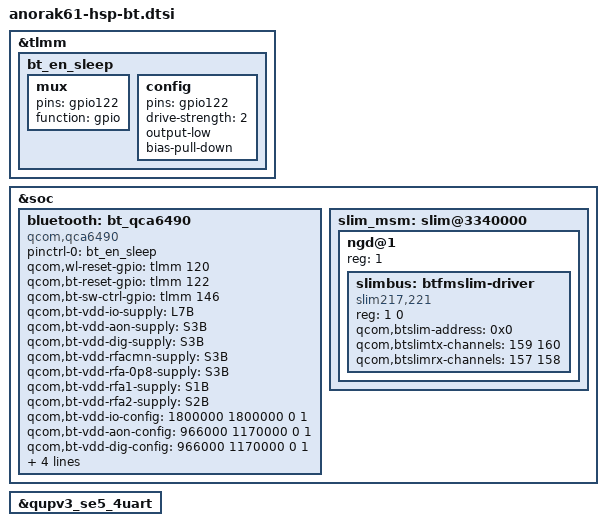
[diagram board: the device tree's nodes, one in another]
#include <dt-bindings/interconnect/qcom,pineapple.h>

&tlmm {
        bt_en_sleep: bt_en_sleep {
                mux {
                        pins = "gpio122";
                        function = "gpio";
                };

                config {
                        pins = "gpio122";
                        drive-strength = <2>;
                        output-low;
                        bias-pull-down;
                };
        };
};


&soc {
	bluetooth: bt_qca6490 {
		compatible = "qcom,qca6490";
		pinctrl-names = "default";
		pinctrl-0 = <&bt_en_sleep>;
		qcom,wl-reset-gpio = <&tlmm 120 0>; /* WL_CTRL */
		qcom,bt-reset-gpio = <&tlmm 122 0>; /* BT_EN */
		qcom,bt-sw-ctrl-gpio = <&tlmm 146 0>; /* SW_CTRL */
		qcom,bt-vdd-io-supply = <&L7B>;  /* IO */
		qcom,bt-vdd-aon-supply = <&S3B>;
		qcom,bt-vdd-dig-supply = <&S3B>; /* BT_CX_MX */
		qcom,bt-vdd-rfacmn-supply = <&S3B>;
		qcom,bt-vdd-rfa-0p8-supply = <&S3B>;
		qcom,bt-vdd-rfa1-supply = <&S1B>; /* RFA 1p7 */
		qcom,bt-vdd-rfa2-supply = <&S2B>; /* RFA 1p2 */
		/* Max Voltages are derived from the buck Max Voltage */
		qcom,bt-vdd-io-config = <1800000 1800000 0 1>;
		qcom,bt-vdd-aon-config = <966000 1170000 0 1>;
		qcom,bt-vdd-dig-config = <966000 1170000 0 1>;
		qcom,bt-vdd-rfacmn-config  = <966000 1170000 0 1>;
		qcom,bt-vdd-rfa-0p8-config  = <966000 1170000 0 1>;
		qcom,bt-vdd-rfa1-config = <1900000 2040000 0 1>;
		qcom,bt-vdd-rfa2-config = <1350000 2024000 0 1>;
	};

	slim_msm: slim@3340000 {
		status =  "ok";
		ngd@1 {
			reg = <1>;
			#address-cells = <1>;
			#size-cells = <1>;
			//slimbus child nodes
			slimbus: btfmslim-driver {
				compatible = "slim217,221";
				reg = <1 0>;
				qcom,btslim-address  = <0x0>; /* BT SLIM EP address*/
				qcom,btslimtx-channels = <159 160>; /* slimbus FM_Tx, SCO_Tx channels */
				qcom,btslimrx-channels = <157 158>; /* slimbus SCO_A2DP_Rx A2DP_Rx */
			};
		};
	};
};

//uart instance
&qupv3_se5_4uart {
	status = "ok";
};
